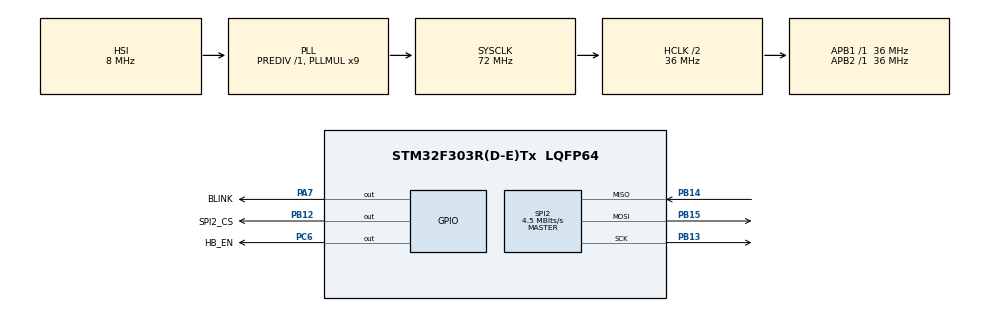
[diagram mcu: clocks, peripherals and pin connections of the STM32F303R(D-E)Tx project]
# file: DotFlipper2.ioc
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Mcu.Family=STM32F3
Mcu.Name=STM32F303R(D-E)Tx
Mcu.Package=LQFP64
NVIC.PriorityGroup=NVIC_PRIORITYGROUP_4
NVIC.SPI2_IRQn=true\:0\:0\:false\:false\:true\:true\:true\:true
PA7.GPIO_Label=BLINK
PA7.Signal=GPIO_Output
PB12.GPIO_Label=SPI2_CS
PB12.GPIO_Speed=GPIO_SPEED_FREQ_HIGH
PB12.Signal=GPIO_Output
PB13.Mode=Full_Duplex_Master
PB13.Signal=SPI2_SCK
PB14.Mode=Full_Duplex_Master
PB14.Signal=SPI2_MISO
PB15.Mode=Full_Duplex_Master
PB15.Signal=SPI2_MOSI
PC6.GPIO_Label=HB_EN
PC6.Signal=GPIO_Output
PF0-OSC_IN.Mode=HSE-External-Oscillator
PF0-OSC_IN.Signal=RCC_OSC_IN
PF1-OSC_OUT.Mode=HSE-External-Oscillator
PF1-OSC_OUT.Signal=RCC_OSC_OUT
ProjectManager.HeapSize=0x200
ProjectManager.StackSize=0x400
ProjectManager.TargetToolchain=STM32CubeIDE
RCC.AHBCLKDivider=RCC_SYSCLK_DIV2
RCC.AHBFreq_Value=36000000
RCC.APB1Freq_Value=36000000
RCC.APB1TimFreq_Value=36000000
RCC.APB2Freq_Value=36000000
RCC.APB2TimFreq_Value=36000000
RCC.CortexFreq_Value=36000000
RCC.HCLKFreq_Value=36000000
RCC.HSE_VALUE=16000000
RCC.HSI_VALUE=8000000
RCC.LSE_VALUE=32768
RCC.PLLMUL=RCC_PLL_MUL9
RCC.SYSCLKFreq_VALUE=72000000
RCC.SYSCLKSourceVirtual=RCC_SYSCLKSOURCE_PLLCLK
RCC.USBFreq_Value=72000000
SPI2.BaudRatePrescaler=SPI_BAUDRATEPRESCALER_8
SPI2.CLKPhase=SPI_PHASE_2EDGE
SPI2.CalculateBaudRate=4.5 MBits/s
SPI2.DataSize=SPI_DATASIZE_16BIT
SPI2.Direction=SPI_DIRECTION_2LINES
SPI2.FirstBit=SPI_FIRSTBIT_LSB
SPI2.Mode=SPI_MODE_MASTER
SPI2.VirtualType=VM_MASTER
board=custom

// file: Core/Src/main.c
/* USER CODE BEGIN Header */
/**
  ******************************************************************************
  * @file           : main.c
  * @brief          : Main program body
  ******************************************************************************
  * @attention
  *
  * Copyright (c) 2022 STMicroelectronics.
  * All rights reserved.
  *
  * This software is licensed under terms that can be found in the LICENSE file
  * in the root directory of this software component.
  * If no LICENSE file comes with this software, it is provided AS-IS.
  *
  ******************************************************************************
  */
/* USER CODE END Header */
#include "main.h"
#include "spi.h"
#include "gpio.h"

/* USER CODE BEGIN Includes */
#include "MATRIX.h"
//#include "DISPLAY.h"

/* USER CODE END Includes */

/* USER CODE BEGIN PD */
#define BUFFERLENGHT 12
#define DAISYCHAINLENGHT 5
#define WIDTH 30
#define HEIGHT 12
/* USER CODE END PD */

/* USER CODE BEGIN PV */

uint8_t TXBuf[DAISYCHAINLENGHT * 2];
uint8_t RXBuf[DAISYCHAINLENGHT * 2];

/* USER CODE END PV */

void SystemClock_Config(void);

int main(void)
{
  /* USER CODE BEGIN 1 */

	  HAL_GPIO_WritePin(HB_EN_GPIO_Port, HB_EN_Pin, 1);
	  HAL_GPIO_WritePin(SPI2_CS_GPIO_Port, SPI2_CS_Pin, 1);

  /* USER CODE END 1 */

  /* MCU Configuration--------------------------------------------------------*/

  /* Reset of all peripherals, Initializes the Flash interface and the Systick. */
  HAL_Init();

  /* Configure the system clock */
  SystemClock_Config();

  /* Initialize all configured peripherals */
  MX_GPIO_Init();
  MX_SPI2_Init();

  /* Infinite loop */
  /* USER CODE BEGIN WHILE */
  while (1)
  {

	  setPixel(0, 0, 1, TXBuf, RXBuf, DAISYCHAINLENGHT, hspi2);

	  HAL_Delay(1000);

	  setPixel(0, 0, 0, TXBuf, RXBuf, DAISYCHAINLENGHT, hspi2);

	  HAL_Delay(1000);
    /* USER CODE END WHILE */

  }
}

void SystemClock_Config(void)
{
  RCC_OscInitTypeDef RCC_OscInitStruct = {0};
  RCC_ClkInitTypeDef RCC_ClkInitStruct = {0};

  /** Initializes the RCC Oscillators according to the specified parameters
  * in the RCC_OscInitTypeDef structure.
  */
  RCC_OscInitStruct.OscillatorType = RCC_OSCILLATORTYPE_HSI;
  RCC_OscInitStruct.HSIState = RCC_HSI_ON;
  RCC_OscInitStruct.HSICalibrationValue = RCC_HSICALIBRATION_DEFAULT;
  RCC_OscInitStruct.PLL.PLLState = RCC_PLL_ON;
  RCC_OscInitStruct.PLL.PLLSource = RCC_PLLSOURCE_HSI;
  RCC_OscInitStruct.PLL.PLLMUL = RCC_PLL_MUL9;
  RCC_OscInitStruct.PLL.PREDIV = RCC_PREDIV_DIV1;
  if (HAL_RCC_OscConfig(&RCC_OscInitStruct) != HAL_OK)
  {
    Error_Handler();
  }

  /** Initializes the CPU, AHB and APB buses clocks
  */
  RCC_ClkInitStruct.ClockType = RCC_CLOCKTYPE_HCLK|RCC_CLOCKTYPE_SYSCLK
                              |RCC_CLOCKTYPE_PCLK1|RCC_CLOCKTYPE_PCLK2;
  RCC_ClkInitStruct.SYSCLKSource = RCC_SYSCLKSOURCE_PLLCLK;
  RCC_ClkInitStruct.AHBCLKDivider = RCC_SYSCLK_DIV2;
  RCC_ClkInitStruct.APB1CLKDivider = RCC_HCLK_DIV1;
  RCC_ClkInitStruct.APB2CLKDivider = RCC_HCLK_DIV1;

  if (HAL_RCC_ClockConfig(&RCC_ClkInitStruct, FLASH_LATENCY_1) != HAL_OK)
  {
    Error_Handler();
  }
}

void Error_Handler(void)
{
  __disable_irq();
  while (1)
  {
  }
}
